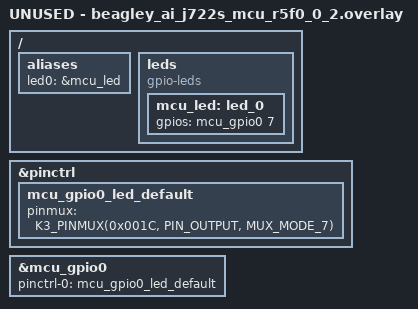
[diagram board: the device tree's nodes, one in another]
/*
 * SPDX-License-Identifier: Apache-2.0
 */

#include <zephyr/dt-bindings/gpio/gpio.h>

 / {
    aliases {
        led0 = &mcu_led;
    };

    leds {
        compatible = "gpio-leds";
        mcu_led: led_0 {
            gpios = <&mcu_gpio0 7 GPIO_ACTIVE_HIGH>;
        };
    };
};

&pinctrl {
    mcu_gpio0_led_default: mcu_gpio0_led_default {
        pinmux = <K3_PINMUX(0x001C, PIN_OUTPUT, MUX_MODE_7)>; /* (B5) MCU_UART0_CTSn.MCU_GPIO0_7 */
    };
};

&mcu_gpio0 {
    pinctrl-0 = <&mcu_gpio0_led_default>;
    pinctrl-names = "default";
    status = "okay";
};
